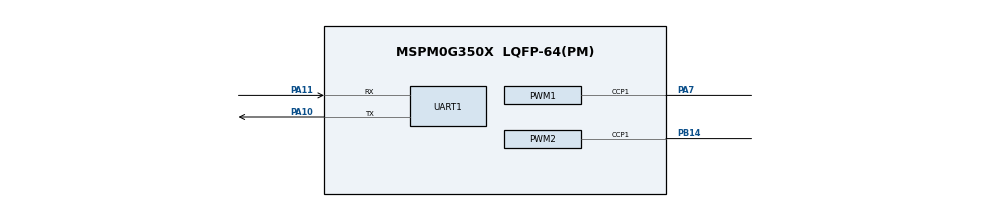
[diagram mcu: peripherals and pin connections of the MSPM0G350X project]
/**
 * automatically applied on subsequent loads via the GUI or CLI.
 * @cliArgs --device "MSPM0G350X" --part "Default" --package "LQFP-64(PM)" --product "mspm0_sdk@2.10.00.04"
 * @versions {"tool":"1.26.2+4477"}
 */

const ADC12  = scripting.addModule("/ti/driverlib/ADC12", {}, false);
const ADC121 = ADC12.addInstance();
const ADC122 = ADC12.addInstance();
const GPIO   = scripting.addModule("/ti/driverlib/GPIO", {}, false);
const GPIO1  = GPIO.addInstance();
const GPIO2  = GPIO.addInstance();
const GPIO3  = GPIO.addInstance();
const GPIO4  = GPIO.addInstance();
const GPIO5  = GPIO.addInstance();
const PWM    = scripting.addModule("/ti/driverlib/PWM", {}, false);
const PWM1   = PWM.addInstance();
const PWM2   = PWM.addInstance();
const SYSCTL = scripting.addModule("/ti/driverlib/SYSCTL");
const UART   = scripting.addModule("/ti/driverlib/UART", {}, false);
const UART1  = UART.addInstance();
const Board  = scripting.addModule("/ti/driverlib/Board", {}, false);

/*
 * lkc hardware map verified from the schematic and PCB measurements:
 * - TB6612: PWMA PB14/TIMG12_CCP1, PWMB PA7/TIMG7_CCP1.
 * - TB6612 direction: AIN1 PA13, AIN2 PB10, BIN1 PB9, BIN2 PB6.
 * - TB6612 STBY is tied to +5V, so no software STBY pin is used.
 * - Grayscale S1..S8: PB19, PB17, PA16, PA14, PB20, PB25, PA25, PA27.
 * - Logical left: U16/R1, B bridge, encoder A2/B2 PB4/PB5.
 * - Logical right: U6/L1, A bridge, encoder A1/B1 PB11/PB12.
 * - UART0 for external MS901M: TX PA10, RX PA11.
 * - OLED software I2C: SCL PA1, SDA PA0.
 * - RUN_LED uses the on-board active-low LED1 on PA15.
 */

GPIO1.$name                         = "TB6612_PORTA";
GPIO1.port                          = "PORTA";
GPIO1.associatedPins.create(1);
GPIO1.associatedPins[0].$name       = "AIN1";
GPIO1.associatedPins[0].assignedPin = "13";

GPIO2.$name                         = "TB6612_PORTB";
GPIO2.port                          = "PORTB";
GPIO2.associatedPins.create(3);
GPIO2.associatedPins[0].$name       = "AIN2";
GPIO2.associatedPins[0].assignedPin = "10";
GPIO2.associatedPins[1].$name       = "BIN1";
GPIO2.associatedPins[1].assignedPin = "9";
GPIO2.associatedPins[2].$name       = "BIN2";
GPIO2.associatedPins[2].assignedPin = "6";

GPIO3.$name                              = "ENCODER_PORTB";
GPIO3.port                               = "PORTB";
GPIO3.associatedPins.create(4);
GPIO3.associatedPins[0].$name            = "LEFT_A";
GPIO3.associatedPins[0].assignedPin      = "4";
GPIO3.associatedPins[0].direction        = "INPUT";
GPIO3.associatedPins[0].internalResistor = "PULL_UP";
GPIO3.associatedPins[0].interruptEn      = true;
GPIO3.associatedPins[0].polarity         = "RISE_FALL";
GPIO3.associatedPins[1].$name            = "LEFT_B";
GPIO3.associatedPins[1].assignedPin      = "5";
GPIO3.associatedPins[1].direction        = "INPUT";
GPIO3.associatedPins[1].internalResistor = "PULL_UP";
GPIO3.associatedPins[2].$name            = "RIGHT_A";
GPIO3.associatedPins[2].assignedPin      = "11";
GPIO3.associatedPins[2].direction        = "INPUT";
GPIO3.associatedPins[2].internalResistor = "PULL_UP";
GPIO3.associatedPins[2].interruptEn      = true;
GPIO3.associatedPins[2].polarity         = "RISE_FALL";
GPIO3.associatedPins[3].$name            = "RIGHT_B";
GPIO3.associatedPins[3].assignedPin      = "12";
GPIO3.associatedPins[3].direction        = "INPUT";
GPIO3.associatedPins[3].internalResistor = "PULL_UP";

GPIO4.$name                          = "OLED_I2C";
GPIO4.port                           = "PORTA";
GPIO4.associatedPins.create(2);
GPIO4.associatedPins[0].$name        = "SCL";
GPIO4.associatedPins[0].assignedPin  = "1";
GPIO4.associatedPins[0].initialValue = "SET";
GPIO4.associatedPins[1].$name        = "SDA";
GPIO4.associatedPins[1].assignedPin  = "0";
GPIO4.associatedPins[1].initialValue = "SET";

GPIO5.$name                          = "RUN_LED";
GPIO5.port                           = "PORTA";
GPIO5.associatedPins[0].$name        = "LED";
GPIO5.associatedPins[0].assignedPin  = "15";
GPIO5.associatedPins[0].initialValue = "SET";

PWM1.$name                      = "PWM_LEFT";
PWM1.timerStartTimer            = true;
PWM1.clockDivider               = 8;
PWM1.timerCount                 = 1000;
PWM1.ccIndex                    = [1];
PWM1.peripheral.$assign         = "TIMG7";
PWM1.peripheral.ccp1Pin.$assign = "PA7";
PWM1.PWM_CHANNEL_1.$name        = "PWMB";
PWM1.PWM_CHANNEL_1.dutyCycle    = 0;

PWM2.$name                      = "PWM_RIGHT";
PWM2.timerStartTimer            = true;
PWM2.clockDivider               = 8;
PWM2.timerCount                 = 1000;
PWM2.ccIndex                    = [1];
PWM2.peripheral.$assign         = "TIMG12";
PWM2.peripheral.ccp1Pin.$assign = "PB14";
PWM2.PWM_CHANNEL_1.$name        = "PWMA";
PWM2.PWM_CHANNEL_1.dutyCycle    = 0;

/* ADC0 samples S4..S8 in one software-triggered sequence. */
ADC121.$name                       = "TRACKING_ADC0";
ADC121.sampClkSrc                  = "DL_ADC12_CLOCK_ULPCLK";
ADC121.sampClkDiv                  = "DL_ADC12_CLOCK_DIVIDE_8";
ADC121.powerDownMode               = "DL_ADC12_POWER_DOWN_MODE_MANUAL";
ADC121.sampleTime0                 = "40 us";
ADC121.samplingOperationMode       = "sequence";
ADC121.endAdd                      = 4;
ADC121.adcMem0chansel              = "DL_ADC12_INPUT_CHAN_12";
ADC121.adcMem1chansel              = "DL_ADC12_INPUT_CHAN_6";
ADC121.adcMem2chansel              = "DL_ADC12_INPUT_CHAN_4";
ADC121.adcMem3chansel              = "DL_ADC12_INPUT_CHAN_2";
ADC121.adcMem4chansel              = "DL_ADC12_INPUT_CHAN_0";
ADC121.adcMem4trig                 = "DL_ADC12_TRIGGER_MODE_TRIGGER_NEXT";
ADC121.adcMem0avgen                = true;
ADC121.adcMem1avgen                = true;
ADC121.adcMem2avgen                = true;
ADC121.adcMem3avgen                = true;
ADC121.adcMem4avgen                = true;
ADC121.hwNumerator                 = "DL_ADC12_HW_AVG_NUM_ACC_4";
ADC121.hwDenominator               = "DL_ADC12_HW_AVG_DEN_DIV_BY_4";
ADC121.peripheral.$assign          = "ADC0";
ADC121.peripheral.adcPin12.$assign = "PA14";
ADC121.peripheral.adcPin6.$assign  = "PB20";
ADC121.peripheral.adcPin4.$assign  = "PB25";
ADC121.peripheral.adcPin2.$assign  = "PA25";
ADC121.peripheral.adcPin0.$assign  = "PA27";

/* ADC1 samples S1..S3 in one software-triggered sequence. */
ADC122.$name                      = "TRACKING_ADC1";
ADC122.sampClkSrc                 = "DL_ADC12_CLOCK_ULPCLK";
ADC122.sampClkDiv                 = "DL_ADC12_CLOCK_DIVIDE_8";
ADC122.powerDownMode              = "DL_ADC12_POWER_DOWN_MODE_MANUAL";
ADC122.sampleTime0                = "40 us";
ADC122.samplingOperationMode      = "sequence";
ADC122.endAdd                     = 2;
ADC122.adcMem0chansel             = "DL_ADC12_INPUT_CHAN_6";
ADC122.adcMem1chansel             = "DL_ADC12_INPUT_CHAN_4";
ADC122.adcMem2chansel             = "DL_ADC12_INPUT_CHAN_1";
ADC122.adcMem2trig                = "DL_ADC12_TRIGGER_MODE_TRIGGER_NEXT";
ADC122.adcMem0avgen               = true;
ADC122.adcMem1avgen               = true;
ADC122.adcMem2avgen               = true;
ADC122.hwNumerator                = "DL_ADC12_HW_AVG_NUM_ACC_4";
ADC122.hwDenominator              = "DL_ADC12_HW_AVG_DEN_DIV_BY_4";
ADC122.peripheral.$assign         = "ADC1";
ADC122.peripheral.adcPin6.$assign = "PB19";
ADC122.peripheral.adcPin4.$assign = "PB17";
ADC122.peripheral.adcPin1.$assign = "PA16";

UART1.$name                    = "UART_0";
UART1.enabledInterrupts        = ["BREAK_ERROR","FRAMING_ERROR","NOISE_ERROR","OVERRUN_ERROR","PARITY_ERROR","RX","RX_TIMEOUT_ERROR"];
UART1.targetBaudRate           = 115200;
UART1.peripheral.$assign       = "UART0";
UART1.peripheral.txPin.$assign = "PA10";
UART1.peripheral.rxPin.$assign = "PA11";

SYSCTL.forceDefaultClkConfig = true;

GPIO1.associatedPins[0].pin.$suggestSolution = "PA13";
GPIO2.associatedPins[0].pin.$suggestSolution = "PB10";
GPIO2.associatedPins[1].pin.$suggestSolution = "PB9";
GPIO2.associatedPins[2].pin.$suggestSolution = "PB6";
GPIO3.associatedPins[0].pin.$suggestSolution = "PB4";
GPIO3.associatedPins[1].pin.$suggestSolution = "PB5";
GPIO3.associatedPins[2].pin.$suggestSolution = "PB11";
GPIO3.associatedPins[3].pin.$suggestSolution = "PB12";
GPIO4.associatedPins[0].pin.$suggestSolution = "PA1";
GPIO4.associatedPins[1].pin.$suggestSolution = "PA0";
GPIO5.associatedPins[0].pin.$suggestSolution = "PA15";
Board.peripheral.$suggestSolution            = "DEBUGSS";
Board.peripheral.swclkPin.$suggestSolution   = "PA20";
Board.peripheral.swdioPin.$suggestSolution   = "PA19";
SYSCTL.peripheral.$suggestSolution           = "SYSCTL";
UART1.peripheral.$suggestSolution            = "UART0";
UART1.peripheral.txPin.$suggestSolution      = "PA10";
UART1.peripheral.rxPin.$suggestSolution      = "PA11";
